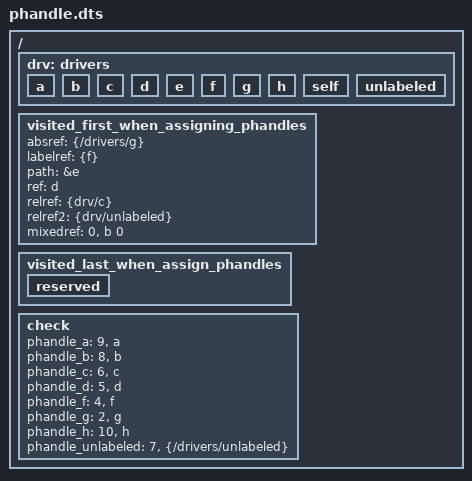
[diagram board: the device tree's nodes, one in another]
/dts-v1/;

/ {
  drv: drivers {
    a: a {}; // phandle 9
    b: b {}; // phandle 8
    c: c {}; // phandle 6
    d: d {}; // phandle 5
    e: e {}; // no phandle assigned
    f: f {}; // phandle 4
    g: g {}; // phandle 2
    h: h {}; // phandle 10
    self: self { phandle = <&self>; }; // phandle 1
    unlabeled {}; // phandle 7
  };

  visited_first_when_assigning_phandles {
    absref = <&{/drivers/g}>;
    labelref = <&{f}>;
    path = &e; // does not trigger an assignment
    ref = <&d>;
    relref = <&{drv/c}>;
    relref2 = <&{drv/unlabeled}>;
    // phandle reference in a more complex propvalue
    mixedref = "foo", /bits/ 32 <0 &b 0>, "bar";
  };

  visited_last_when_assign_phandles {
    reserved {
      phandle = <3>; // excluded from automatic assignment
    };
  };

  check {
    // test properties:
    phandle_a = <9 &a>;
    phandle_b = <8 &b>;
    phandle_c = <6 &c>;
    phandle_d = <5 &d>;
    phandle_f = <4 &f>;
    phandle_g = <2 &g>;
    phandle_h = <10 &h>;
    phandle_unlabeled = <7 &{/drivers/unlabeled}>;
  };
};
